# STM32N645 register map
File version: 1.0
CPU: CM55 r0p1, little endian, no MPU, FPU, vendor SysTick, 8 interrupt priority bits
Registers are 32-bit, read-write, reset 0x0 unless marked. A register's access mark holds for its fields unless they carry their own. Offsets are from the block's base; [hi:lo] are bit positions; {n}, {i} and the like mark numbered series.

## TAMP — Tamper and backup registers
Base 0x46004400
Same registers: TAMP_S 0x56004400
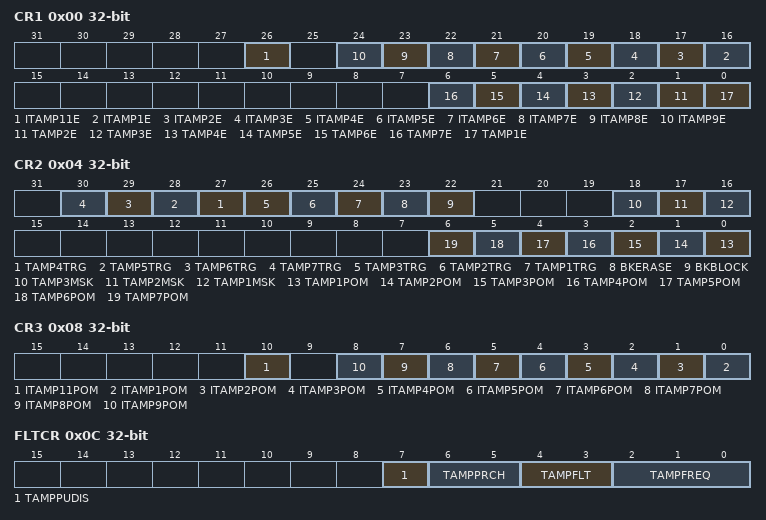
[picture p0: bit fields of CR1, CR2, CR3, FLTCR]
0x00 CR1 — TAMP control register 1
  [26] ITAMP11E — Internal tamper 11 enable
  [n+15] ITAMP{n}E (n=1..9) — Internal tamper {n} enable
  [n-1] TAMP{n}E (n=2..7) — Tamper detection on TAMP_IN{n} enable less than sup>(1) less than /sup>
  [0] TAMP1E — Tamper detection on TAMP_IN1 enable
0x04 CR2 access per field — TAMP control register 2
  [n+23] TAMP{n}TRG rw (n=4..7) — Active level for tamper {n} input (active mode disabled)
  [26] TAMP3TRG rw — Active level for tamper 3 input
  [25] TAMP2TRG rw — Active level for tamper 2 input
  [24] TAMP1TRG rw — Active level for tamper 1 input
  [23] BKERASE wo — Backup registers and device secrets less than sup>(1) less than /sup> erase
  [22] BKBLOCK rw — Backup registers and device secrets less than sup>(1) less than /sup> access blocked
  [18] TAMP3MSK rw — Tamper 3 mask
  [17] TAMP2MSK rw — Tamper 2 mask
  [16] TAMP1MSK rw — Tamper 1 mask
  [n-1] TAMP{n}POM rw (n=1..7) — Tamper {n} potential mode
0x08 CR3 — TAMP control register 3
  [10] ITAMP11POM — Internal tamper 11 potential mode
  [n-1] ITAMP{n}POM (n=1..9) — Internal tamper {n} potential mode
0x0C FLTCR — TAMP filter control register
  [7] TAMPPUDIS — TAMP_INx pull-up disable
  [6:5] TAMPPRCH — TAMP_INx precharge duration
  [4:3] TAMPFLT — TAMP_INx filter count
  [2:0] TAMPFREQ — Tamper sampling frequency
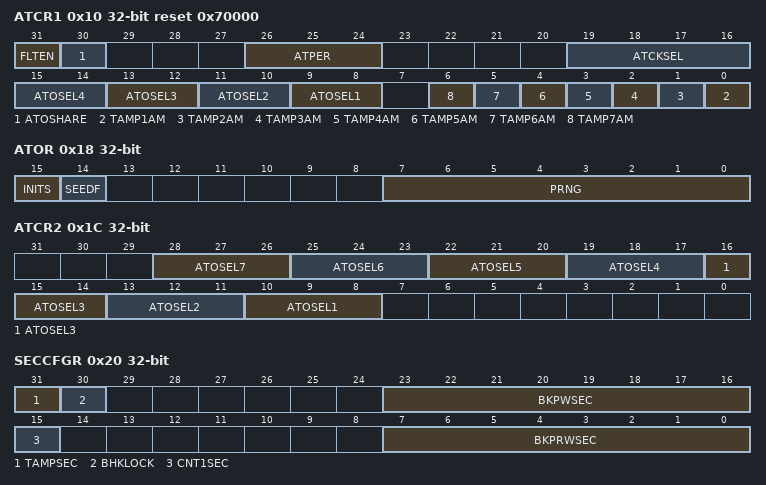
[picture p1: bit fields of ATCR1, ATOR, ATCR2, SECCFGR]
0x10 ATCR1 reset 0x70000 — TAMP active tamper control register 1
  [31] FLTEN — Active tamper filter enable
  [30] ATOSHARE — Active tamper output sharing
  [26:24] ATPER — Active tamper output change period
  [19:16] ATCKSEL — Active tamper RTC asynchronous prescaler clock selection
  [2n+7:2n+6] ATOSEL{n} (n=1..4) — Active tamper shared output {n} selection
  [n-1] TAMP{n}AM (n=1..7) — Tamper {n} active mode
0x14 ATSEEDR wo — TAMP active tamper seed register
  [31:0] SEED — Pseudo-random generator seed value
0x18 ATOR ro — TAMP active tamper output register
  [15] INITS — Active tamper initialization status
  [14] SEEDF — Seed running flag
  [7:0] PRNG — Pseudo-random generator value
0x1C ATCR2 — TAMP active tamper control register 2
  [3n+7:3n+5] ATOSEL{n} (n=1..7) — Active tamper shared output {n} selection
0x20 SECCFGR — TAMP secure configuration register
  [31] TAMPSEC — Tamper protection (excluding monotonic counters and backup registers)
  [30] BHKLOCK — Boot hardware key lock
  [23:16] BKPWSEC — Backup registers write protection offset
  [15] CNT1SEC — Monotonic counter 1 secure protection
  [7:0] BKPRWSEC — Backup registers read/write protection offset
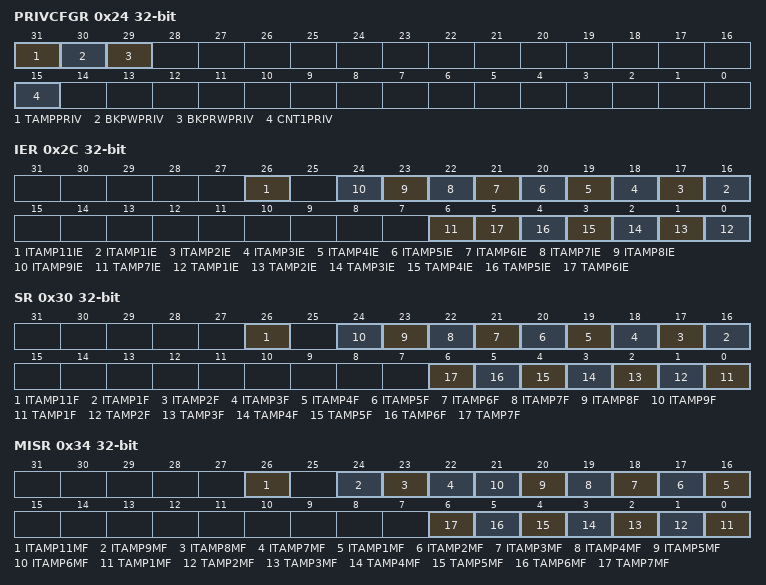
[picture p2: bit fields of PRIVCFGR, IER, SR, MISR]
0x24 PRIVCFGR — TAMP privilege configuration register
  [31] TAMPPRIV — Tamper privilege protection (excluding backup registers)
  [30] BKPWPRIV — Backup registers zone 2 privilege protection
  [29] BKPRWPRIV — Backup registers zone 1 privilege protection
  [15] CNT1PRIV — Monotonic counter 1 privilege protection
0x2C IER — TAMP interrupt enable register
  [26] ITAMP11IE — Internal tamper 11 interrupt enable
  [n+15] ITAMP{n}IE (n=1..9) — Internal tamper {n} interrupt enable
  [6] TAMP7IE — Tamper 7interrupt enable
  [n-1] TAMP{n}IE (n=1..6) — Tamper {n} interrupt enable
0x30 SR ro — TAMP status register
  [26] ITAMP11F — Internal tamper 11 flag
  [n+15] ITAMP{n}F (n=1..9) — Internal tamper {n} flag
  [n-1] TAMP{n}F (n=1..7) — TAMP{n} detection flag
0x34 MISR ro — TAMP non-secure masked interrupt status register
  [26] ITAMP11MF — internal tamper 11 non-secure interrupt masked flag
  [24] ITAMP9MF — internal tamper 9 non-secure interrupt masked flag
  [23] ITAMP8MF — Internal tamper 8 non-secure interrupt masked flag
  [22] ITAMP7MF — Internal tamper 7 tamper non-secure interrupt masked flag
  [n+15] ITAMP{n}MF (n=1..6) — Internal tamper {n} non-secure interrupt masked flag
  [n-1] TAMP{n}MF (n=1..7) — TAMP{n} non-secure interrupt masked flag
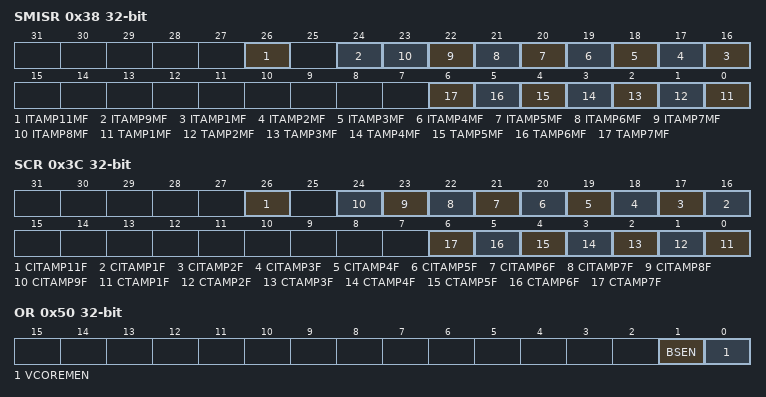
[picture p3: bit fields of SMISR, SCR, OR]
0x38 SMISR ro — TAMP secure masked interrupt status register
  [26] ITAMP11MF — internal tamper 11 secure interrupt masked flag
  [24] ITAMP9MF — internal tamper 9 secure interrupt masked flag
  [n+15] ITAMP{n}MF (n=1..8) — Internal tamper {n} secure interrupt masked flag
  [n-1] TAMP{n}MF (n=1..7) — TAMP{n} secure interrupt masked flag
0x3C SCR wo — TAMP status clear register
  [26] CITAMP11F — Clear ITAMP11 detection flag
  [n+15] CITAMP{n}F (n=1..9) — Clear ITAMP{n} detection flag
  [n-1] CTAMP{n}F (n=1..7) — Clear TAMP{n} detection flag
0x40 COUNT1R ro — TAMP monotonic counter 1 register
  [31:0] COUNT — This register is read-only only and is incremented by one when a write access is done to this register. This register cannot roll-over and is frozen when reaching the maximum value.
0x50 OR — TAMP option register
  [1] BSEN — Boundary scan enable
  [0] VCOREMEN — V less than sub>CORE less than /sub> monitoring
0x54 RPCFGR — TAMP resources protection configuration register
  [0] RPCFG0 — Configurable resource 0 protection
{0x100+4i} BKP{i}R (i=0..31) — TAMP backup {i} register
  [31:0] BKP — The application can write or read data to and from these registers.
